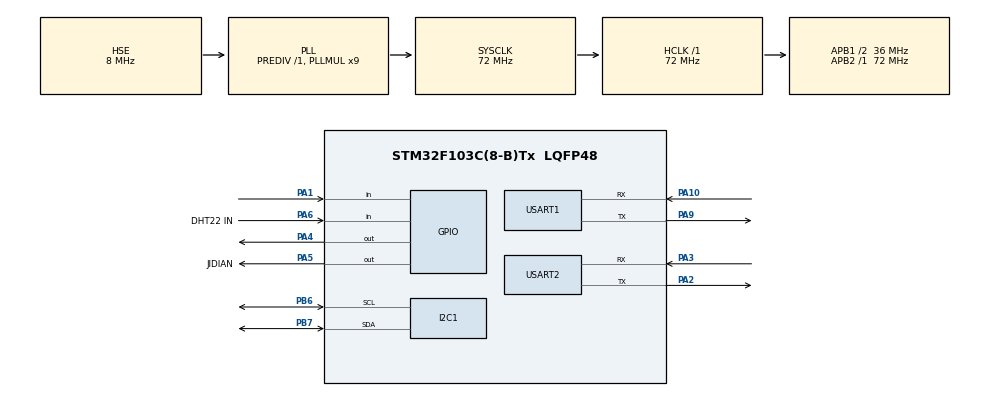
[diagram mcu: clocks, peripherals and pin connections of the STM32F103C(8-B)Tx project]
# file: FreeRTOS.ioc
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FREERTOS.Mutexes01=sem_i2c,Dynamic,NULL
FREERTOS.Queues01=queue_sensor,1,SensorData_t,0,Dynamic,NULL,NULL;queue_alarm,5,AlarmEvent_t,0,Dynamic,NULL,NULL
FREERTOS.Tasks01=defaultTask,0,128,StartDefaultTask,Default,NULL,Dynamic,NULL,NULL;Sensor,-1,256,vTaskSensorCollect,As weak,NULL,Dynamic,NULL,NULL;Display,-2,256,vTaskDisplay,As weak,NULL,Dynamic,NULL,NULL;Control,0,256,vTaskControl,As weak,NULL,Dynamic,NULL,NULL;Comm,-1,512,vTaskCommunication,As weak,NULL,Dynamic,NULL,NULL;Log,-2,256,vTaskLog,As weak,NULL,Dynamic,NULL,NULL
FREERTOS.configTOTAL_HEAP_SIZE=10240
Mcu.Family=STM32F1
Mcu.Name=STM32F103C(8-B)Tx
Mcu.Package=LQFP48
NVIC.PriorityGroup=NVIC_PRIORITYGROUP_4
NVIC.USART2_IRQn=true\:5\:0\:true\:false\:true\:true\:true\:true\:true
PA1.GPIO_PuPd=GPIO_PULLUP
PA1.Signal=GPIO_Input
PA10.Mode=Asynchronous
PA10.Signal=USART1_RX
PA13.Mode=Serial_Wire
PA13.Signal=SYS_JTMS-SWDIO
PA14.Mode=Serial_Wire
PA14.Signal=SYS_JTCK-SWCLK
PA2.Mode=Asynchronous
PA2.Signal=USART2_TX
PA3.Mode=Asynchronous
PA3.Signal=USART2_RX
PA4.PinState=GPIO_PIN_RESET
PA4.Signal=GPIO_Output
PA5.GPIO_Label=JIDIAN
PA5.Signal=GPIO_Output
PA6.GPIO_Label=DHT22 IN
PA6.GPIO_PuPd=GPIO_NOPULL
PA6.Signal=GPIO_Input
PA9.Mode=Asynchronous
PA9.Signal=USART1_TX
PB6.Mode=I2C
PB6.Signal=I2C1_SCL
PB7.Mode=I2C
PB7.Signal=I2C1_SDA
PD0-OSC_IN.Mode=HSE-External-Oscillator
PD0-OSC_IN.Signal=RCC_OSC_IN
PD1-OSC_OUT.Mode=HSE-External-Oscillator
PD1-OSC_OUT.Signal=RCC_OSC_OUT
ProjectManager.HeapSize=0x200
ProjectManager.StackSize=0x400
ProjectManager.TargetToolchain=MDK-ARM V5.27
RCC.AHBFreq_Value=72000000
RCC.APB1CLKDivider=RCC_HCLK_DIV2
RCC.APB1Freq_Value=36000000
RCC.APB1TimFreq_Value=72000000
RCC.APB2Freq_Value=72000000
RCC.APB2TimFreq_Value=72000000
RCC.HCLKFreq_Value=72000000
RCC.PLLMUL=RCC_PLL_MUL9
RCC.PLLSourceVirtual=RCC_PLLSOURCE_HSE
RCC.SYSCLKFreq_VALUE=72000000
RCC.SYSCLKSource=RCC_SYSCLKSOURCE_PLLCLK
RCC.USBFreq_Value=72000000
TIM2.Prescaler=71
USART1.VirtualMode=VM_ASYNC
USART2.VirtualMode=VM_ASYNC
VP_FREERTOS_VS_CMSIS_V1.Mode=CMSIS_V1
VP_TIM2_VS_ClockSourceINT.Mode=Internal
board=custom

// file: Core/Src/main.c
/* USER CODE BEGIN Header */
/**
  ******************************************************************************
  * @file           : main.c
  * @brief          : Main program body
  ******************************************************************************
  * @attention
  *
  * Copyright (c) 2026 STMicroelectronics.
  * All rights reserved.
  *
  * This software is licensed under terms that can be found in the LICENSE file
  * in the root directory of this software component.
  * If no LICENSE file comes with this software, it is provided AS-IS.
  *
  ******************************************************************************
  */
/* USER CODE END Header */
#include "main.h"
#include "cmsis_os.h"
#include "i2c.h"
#include "tim.h"
#include "usart.h"
#include "gpio.h"

/* USER CODE BEGIN Includes */
#include <stdio.h>
/* USER CODE END Includes */

void SystemClock_Config(void);
void MX_FREERTOS_Init(void);

/* USER CODE BEGIN 0 */
//重定�?
int fputc(int ch, FILE *f)
{
    HAL_UART_Transmit(&huart1, (uint8_t *)&ch, 1, HAL_MAX_DELAY);
    return ch;
}
/* USER CODE END 0 */

int main(void)
{

  /* MCU Configuration--------------------------------------------------------*/

  /* Reset of all peripherals, Initializes the Flash interface and the Systick. */
  HAL_Init();

  /* Configure the system clock */
  SystemClock_Config();

  /* Initialize all configured peripherals */
  MX_GPIO_Init();
  MX_I2C1_Init();
  MX_TIM2_Init();
  MX_USART1_UART_Init();
  MX_USART2_UART_Init();

  /* Call init function for freertos objects (in cmsis_os2.c) */
  MX_FREERTOS_Init();

  /* Start scheduler */
  osKernelStart();

  /* We should never get here as control is now taken by the scheduler */

  /* Infinite loop */
  while (1)
  {

  }
}

void SystemClock_Config(void)
{
  RCC_OscInitTypeDef RCC_OscInitStruct = {0};
  RCC_ClkInitTypeDef RCC_ClkInitStruct = {0};

  /** Initializes the RCC Oscillators according to the specified parameters
  * in the RCC_OscInitTypeDef structure.
  */
  RCC_OscInitStruct.OscillatorType = RCC_OSCILLATORTYPE_HSE;
  RCC_OscInitStruct.HSEState = RCC_HSE_ON;
  RCC_OscInitStruct.HSEPredivValue = RCC_HSE_PREDIV_DIV1;
  RCC_OscInitStruct.HSIState = RCC_HSI_ON;
  RCC_OscInitStruct.PLL.PLLState = RCC_PLL_ON;
  RCC_OscInitStruct.PLL.PLLSource = RCC_PLLSOURCE_HSE;
  RCC_OscInitStruct.PLL.PLLMUL = RCC_PLL_MUL9;
  if (HAL_RCC_OscConfig(&RCC_OscInitStruct) != HAL_OK)
  {
    Error_Handler();
  }

  /** Initializes the CPU, AHB and APB buses clocks
  */
  RCC_ClkInitStruct.ClockType = RCC_CLOCKTYPE_HCLK|RCC_CLOCKTYPE_SYSCLK
                              |RCC_CLOCKTYPE_PCLK1|RCC_CLOCKTYPE_PCLK2;
  RCC_ClkInitStruct.SYSCLKSource = RCC_SYSCLKSOURCE_PLLCLK;
  RCC_ClkInitStruct.AHBCLKDivider = RCC_SYSCLK_DIV1;
  RCC_ClkInitStruct.APB1CLKDivider = RCC_HCLK_DIV2;
  RCC_ClkInitStruct.APB2CLKDivider = RCC_HCLK_DIV1;

  if (HAL_RCC_ClockConfig(&RCC_ClkInitStruct, FLASH_LATENCY_2) != HAL_OK)
  {
    Error_Handler();
  }
}

void Error_Handler(void)
{
  __disable_irq();
  while (1)
  {
  }
}

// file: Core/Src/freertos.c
/* USER CODE BEGIN Header */
/**
  ******************************************************************************
  * File Name          : freertos.c
  * Description        : Code for freertos applications
  ******************************************************************************
  * @attention
  *
  * Copyright (c) 2026 STMicroelectronics.
  * All rights reserved.
  *
  * This software is licensed under terms that can be found in the LICENSE file
  * in the root directory of this software component.
  * If no LICENSE file comes with this software, it is provided AS-IS.
  *
  ******************************************************************************
  */
/* USER CODE END Header */

#include "FreeRTOS.h"
#include "task.h"
#include "main.h"
#include "cmsis_os.h"

/* USER CODE BEGIN Includes */
#include "stdio.h"
#include "app_tasks.h"
#include "queue.h"
#include "semphr.h"
/* USER CODE END Includes */

osThreadId defaultTaskHandle;
osThreadId SensorHandle;
osThreadId DisplayHandle;
osThreadId ControlHandle;
osThreadId CommHandle;
osThreadId LogHandle;
osMessageQId queue_sensorHandle;
osMessageQId queue_alarmHandle;
osMutexId sem_i2cHandle;

void StartDefaultTask(void const * argument);
void vTaskSensorCollect(void const * argument);
void vTaskDisplay(void const * argument);
void vTaskControl(void const * argument);
void vTaskCommunication(void const * argument);
void vTaskLog(void const * argument);

void MX_FREERTOS_Init(void); /* (MISRA C 2004 rule 8.1) */

/* GetIdleTaskMemory prototype (linked to static allocation support) */
void vApplicationGetIdleTaskMemory( StaticTask_t **ppxIdleTaskTCBBuffer, StackType_t **ppxIdleTaskStackBuffer, uint32_t *pulIdleTaskStackSize );

/* USER CODE BEGIN GET_IDLE_TASK_MEMORY */
static StaticTask_t xIdleTaskTCBBuffer;
static StackType_t xIdleStack[configMINIMAL_STACK_SIZE];

void vApplicationGetIdleTaskMemory( StaticTask_t **ppxIdleTaskTCBBuffer, StackType_t **ppxIdleTaskStackBuffer, uint32_t *pulIdleTaskStackSize )
{
  *ppxIdleTaskTCBBuffer = &xIdleTaskTCBBuffer;
  *ppxIdleTaskStackBuffer = &xIdleStack[0];
  *pulIdleTaskStackSize = configMINIMAL_STACK_SIZE;
  /* place for user code */
}
/* USER CODE END GET_IDLE_TASK_MEMORY */

void MX_FREERTOS_Init(void) {
  /* Create the mutex(es) */
  /* definition and creation of sem_i2c */
  osMutexDef(sem_i2c);
  sem_i2cHandle = osMutexCreate(osMutex(sem_i2c));

  /* Create the queue(s) */
  /* definition and creation of queue_sensor */
  osMessageQDef(queue_sensor, 1, SensorData_t);
  queue_sensorHandle = osMessageCreate(osMessageQ(queue_sensor), NULL);

  /* definition and creation of queue_alarm */
  osMessageQDef(queue_alarm, 5, AlarmEvent_t);
  queue_alarmHandle = osMessageCreate(osMessageQ(queue_alarm), NULL);

  /* Create the thread(s) */
  /* definition and creation of defaultTask */
  osThreadDef(defaultTask, StartDefaultTask, osPriorityNormal, 0, 128);
  defaultTaskHandle = osThreadCreate(osThread(defaultTask), NULL);

  /* definition and creation of Sensor */
  osThreadDef(Sensor, vTaskSensorCollect, osPriorityBelowNormal, 0, 256);
  SensorHandle = osThreadCreate(osThread(Sensor), NULL);

  /* definition and creation of Display */
  osThreadDef(Display, vTaskDisplay, osPriorityLow, 0, 256);
  DisplayHandle = osThreadCreate(osThread(Display), NULL);

  /* definition and creation of Control */
  osThreadDef(Control, vTaskControl, osPriorityNormal, 0, 256);
  ControlHandle = osThreadCreate(osThread(Control), NULL);

  /* definition and creation of Comm */
  osThreadDef(Comm, vTaskCommunication, osPriorityBelowNormal, 0, 512);
  CommHandle = osThreadCreate(osThread(Comm), NULL);

  /* definition and creation of Log */
  osThreadDef(Log, vTaskLog, osPriorityLow, 0, 256);
  LogHandle = osThreadCreate(osThread(Log), NULL);

}

void StartDefaultTask(void const * argument)
{
  /* USER CODE BEGIN StartDefaultTask */
  for(;;)
  {
    printf("[HB] tick=%lu heap_free=%u\r\n",
           (unsigned long)xTaskGetTickCount(),
           (unsigned)xPortGetFreeHeapSize());
    osDelay(1000);
  }
  /* USER CODE END StartDefaultTask */
}

__weak void vTaskSensorCollect(void const * argument)
{
  for(;;)
  {
    osDelay(1);
  }
}

__weak void vTaskDisplay(void const * argument)
{
  for(;;)
  {
    osDelay(1);
  }
}

__weak void vTaskControl(void const * argument)
{
  for(;;)
  {
    osDelay(1);
  }
}

__weak void vTaskCommunication(void const * argument)
{
  for(;;)
  {
    osDelay(1);
  }
}

__weak void vTaskLog(void const * argument)
{
  for(;;)
  {
    osDelay(1);
  }
}
